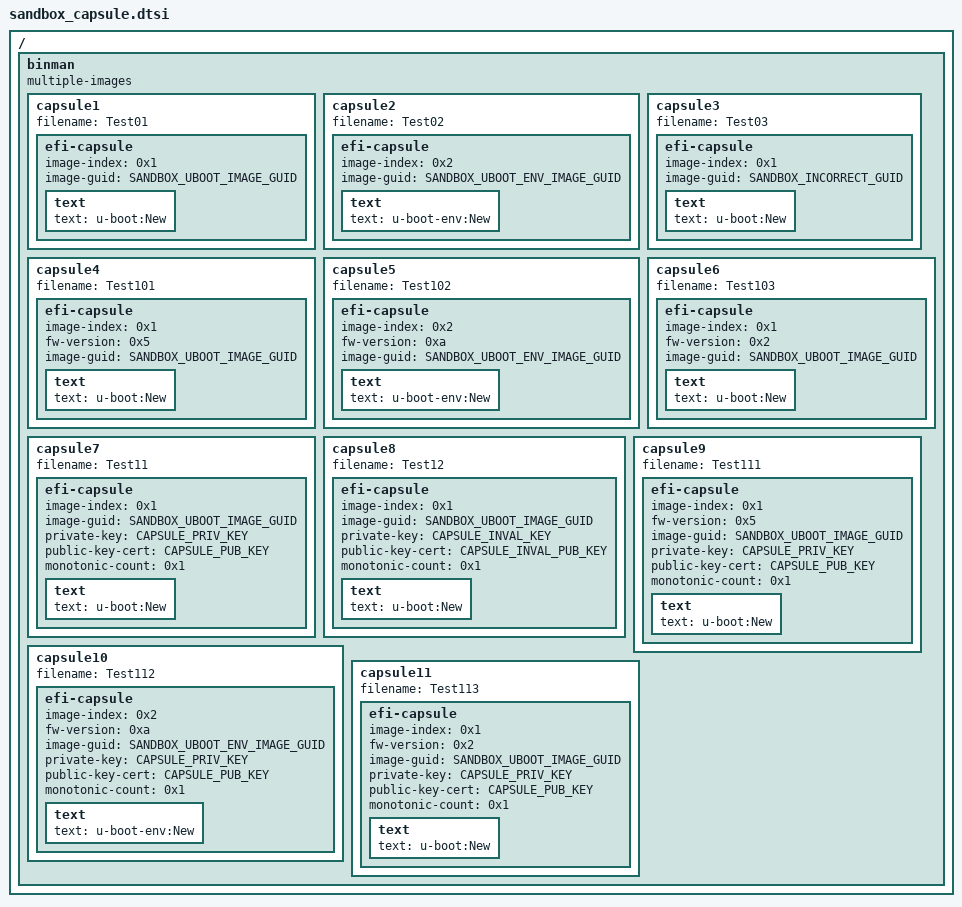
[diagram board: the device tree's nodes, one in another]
// SPDX-License-Identifier: GPL-2.0+
/*
 * Devicetree file with binman nodes needed for generating EFI
 * capsules.
 *
 */

#include <sandbox_efi_capsule.h>

/ {
	binman: binman {
		multiple-images;
	};
};

&binman {
	capsule1 {
		filename = "Test01";
		efi-capsule {
			image-index = <0x1>;
			image-guid = SANDBOX_UBOOT_IMAGE_GUID;

			text {
				text = "u-boot:New";
			};
		};
	};

	capsule2 {
		filename = "Test02";
		efi-capsule {
			image-index = <0x2>;
			image-guid = SANDBOX_UBOOT_ENV_IMAGE_GUID;

			text {
				text = "u-boot-env:New";
			};
		};
	};

	capsule3 {
		filename = "Test03";
		efi-capsule {
			image-index = <0x1>;
			image-guid = SANDBOX_INCORRECT_GUID;

			text {
				text = "u-boot:New";
			};
		};
	};

	capsule4 {
		filename = "Test101";
		efi-capsule {
			image-index = <0x1>;
			fw-version = <0x5>;
			image-guid = SANDBOX_UBOOT_IMAGE_GUID;

			text {
				text = "u-boot:New";
			};
		};
	};

	capsule5 {
		filename = "Test102";
		efi-capsule {
			image-index = <0x2>;
			fw-version = <0xa>;
			image-guid = SANDBOX_UBOOT_ENV_IMAGE_GUID;

			text {
				text = "u-boot-env:New";
			};
		};
	};

	capsule6 {
		filename = "Test103";
		efi-capsule {
			image-index = <0x1>;
			fw-version = <0x2>;
			image-guid = SANDBOX_UBOOT_IMAGE_GUID;

			text {
				text = "u-boot:New";
			};
		};
	};

	capsule7 {
		filename = "Test11";
		efi-capsule {
			image-index = <0x1>;
			image-guid = SANDBOX_UBOOT_IMAGE_GUID;
			private-key = CAPSULE_PRIV_KEY;
			public-key-cert = CAPSULE_PUB_KEY;
			monotonic-count = <0x1>;

			text {
				text = "u-boot:New";
			};
		};
	};

	capsule8 {
		filename = "Test12";
		efi-capsule {
			image-index = <0x1>;
			image-guid = SANDBOX_UBOOT_IMAGE_GUID;
			private-key = CAPSULE_INVAL_KEY;
			public-key-cert = CAPSULE_INVAL_PUB_KEY;
			monotonic-count = <0x1>;

			text {
				text = "u-boot:New";
			};
		};
	};

	capsule9 {
		filename = "Test111";
		efi-capsule {
			image-index = <0x1>;
			fw-version = <0x5>;
			image-guid = SANDBOX_UBOOT_IMAGE_GUID;
			private-key = CAPSULE_PRIV_KEY;
			public-key-cert = CAPSULE_PUB_KEY;
			monotonic-count = <0x1>;

			text {
				text = "u-boot:New";
			};
		};
	};

	capsule10 {
		filename = "Test112";
		efi-capsule {
			image-index = <0x2>;
			fw-version = <0xa>;
			image-guid = SANDBOX_UBOOT_ENV_IMAGE_GUID;
			private-key = CAPSULE_PRIV_KEY;
			public-key-cert = CAPSULE_PUB_KEY;
			monotonic-count = <0x1>;

			text {
				text = "u-boot-env:New";
			};
		};
	};

	capsule11 {
		filename = "Test113";
		efi-capsule {
			image-index = <0x1>;
			fw-version = <0x2>;
			image-guid = SANDBOX_UBOOT_IMAGE_GUID;
			private-key = CAPSULE_PRIV_KEY;
			public-key-cert = CAPSULE_PUB_KEY;
			monotonic-count = <0x1>;

			text {
				text = "u-boot:New";
			};
		};
	};
};
